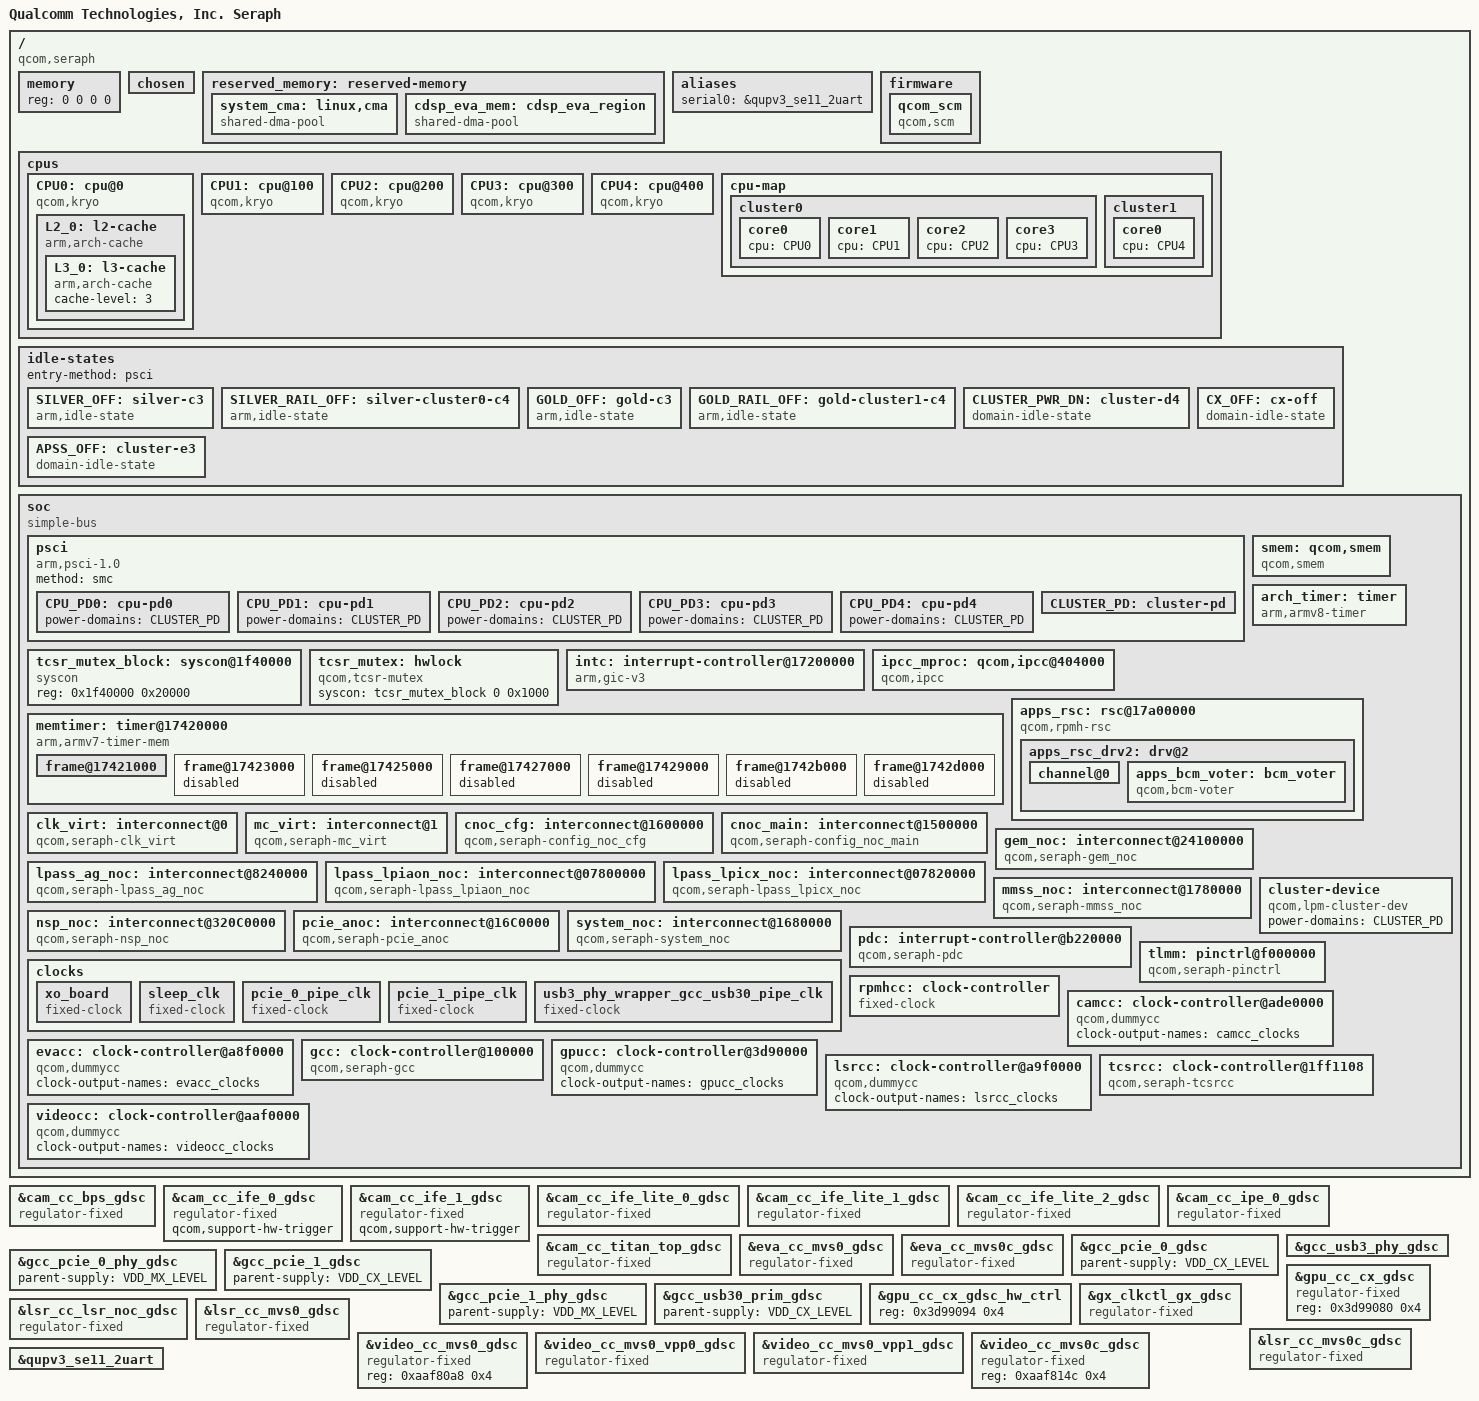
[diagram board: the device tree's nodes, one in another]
#include <dt-bindings/interrupt-controller/arm-gic.h>
#include <dt-bindings/soc/qcom,rpmh-rsc.h>
#include <dt-bindings/clock/qcom,rpmh.h>
#include <dt-bindings/clock/qcom,camcc-seraph.h>
#include <dt-bindings/clock/qcom,evacc-seraph.h>
#include <dt-bindings/clock/qcom,gcc-seraph.h>
#include <dt-bindings/clock/qcom,gpucc-seraph.h>
#include <dt-bindings/clock/qcom,lsrcc-seraph.h>
#include <dt-bindings/clock/qcom,tcsrcc-seraph.h>
#include <dt-bindings/clock/qcom,videocc-seraph.h>
#include <dt-bindings/interconnect/qcom,seraph.h>
#include <dt-bindings/mailbox/qcom-ipcc.h>
#include <dt-bindings/regulator/qcom,rpmh-regulator-levels.h>

/ {
	model = "Qualcomm Technologies, Inc. Seraph";
	compatible = "qcom,seraph";
	qcom,msm-id = <672 0x10000>;
	interrupt-parent = <&intc>;

	#address-cells = <2>;
	#size-cells = <2>;
	memory { device_type = "memory"; reg = <0 0 0 0>; };

	chosen: chosen {
		bootargs = "kpti=0 log_buf_len=256K swiotlb=0 loop.max_part=7 loglevel=8";
	};

	reserved_memory: reserved-memory {};

	aliases {
		serial0 = &qupv3_se11_2uart;
	 };

	firmware: firmware {};

	cpus {
		#address-cells = <2>;
		#size-cells = <0>;

		CPU0: cpu@0 {
			device_type = "cpu";
			compatible = "qcom,kryo";
			reg = <0x0 0x0>;
			enable-method = "psci";
			cpu-idle-states = <&SILVER_OFF &SILVER_RAIL_OFF>;
			power-domains = <&CPU_PD0>;
			power-domain-names = "psci";
			next-level-cache = <&L2_0>;
			capacity-dmips-mhz = <1024>;
			dynamic-power-coefficient = <100>;
			L2_0: l2-cache {
				compatible = "arm,arch-cache";
				cache-level = <2>;
				next-level-cache = <&L3_0>;

				L3_0: l3-cache {
					compatible = "arm,arch-cache";
					cache-level = <3>;
				};
			};
		};

		CPU1: cpu@100 {
			device_type = "cpu";
			compatible = "qcom,kryo";
			reg = <0x0 0x100>;
			enable-method = "psci";
			cpu-idle-states = <&SILVER_OFF &SILVER_RAIL_OFF>;
			power-domains = <&CPU_PD1>;
			power-domain-names = "psci";
			next-level-cache = <&L2_0>;
			capacity-dmips-mhz = <1024>;
			dynamic-power-coefficient = <100>;
		};

		CPU2: cpu@200 {
			device_type = "cpu";
			compatible = "qcom,kryo";
			reg = <0x0 0x200>;
			enable-method = "psci";
			cpu-idle-states = <&SILVER_OFF &SILVER_RAIL_OFF>;
			power-domains = <&CPU_PD2>;
			power-domain-names = "psci";
			next-level-cache = <&L2_0>;
			capacity-dmips-mhz = <1024>;
			dynamic-power-coefficient = <100>;
		};

		CPU3: cpu@300 {
			device_type = "cpu";
			compatible = "qcom,kryo";
			reg = <0x0 0x300>;
			enable-method = "psci";
			cpu-idle-states = <&SILVER_OFF &SILVER_RAIL_OFF>;
			power-domains = <&CPU_PD3>;
			power-domain-names = "psci";
			next-level-cache = <&L2_0>;
			capacity-dmips-mhz = <1024>;
			dynamic-power-coefficient = <100>;
		};

		CPU4: cpu@400 {
			device_type = "cpu";
			compatible = "qcom,kryo";
			reg = <0x0 0x400>;
			enable-method = "psci";
			cpu-idle-states = <&GOLD_OFF &GOLD_RAIL_OFF>;
			power-domains = <&CPU_PD4>;
			power-domain-names = "psci";
			next-level-cache = <&L2_0>;
			capacity-dmips-mhz = <1956>;
			dynamic-power-coefficient = <389>;
		};

		cpu-map {
			cluster0 {
				core0 {
					cpu = <&CPU0>;
				};

				core1 {
					cpu = <&CPU1>;
				};

				core2 {
					cpu = <&CPU2>;
				};

				core3 {
					cpu = <&CPU3>;
				};
			};

			cluster1 {
				core0 {
					cpu = <&CPU4>;
				};
			};
		};
	};

	idle-states {
		entry-method = "psci";

		SILVER_OFF: silver-c3 {  /* C3 */
			compatible = "arm,idle-state";
			idle-state-name = "pc";
			entry-latency-us = <250>;
			exit-latency-us = <900>;
			min-residency-us = <3200>;
			arm,psci-suspend-param = <0x40000003>;
			local-timer-stop;
		};

		SILVER_RAIL_OFF: silver-cluster0-c4 { /* C4 */
			compatible = "arm,idle-state";
			idle-state-name = "rail-pc";
			entry-latency-us = <550>;
			exit-latency-us = <750>;
			min-residency-us = <6700>;
			arm,psci-suspend-param = <0x40000004>;
			local-timer-stop;
		};

		GOLD_OFF: gold-c3 {  /* C3 */
			compatible = "arm,idle-state";
			idle-state-name = "pc";
			entry-latency-us = <400>;
			exit-latency-us = <1100>;
			min-residency-us = <4011>;
			arm,psci-suspend-param = <0x40000003>;
			local-timer-stop;
		};

		GOLD_RAIL_OFF: gold-cluster1-c4 { /* C4 */
			compatible = "arm,idle-state";
			idle-state-name = "rail-pc";
			entry-latency-us = <550>;
			exit-latency-us = <1050>;
			min-residency-us = <7951>;
			arm,psci-suspend-param = <0x40000004>;
			local-timer-stop;
		};

		CLUSTER_PWR_DN: cluster-d4 { /* D4 */
			compatible = "domain-idle-state";
			idle-state-name = "l3-off";
			entry-latency-us = <750>;
			exit-latency-us = <2350>;
			min-residency-us = <9144>;
			arm,psci-suspend-param = <0x41000044>;
		};

		CX_OFF: cx-off { /* Cx Off */
			compatible = "domain-idle-state";
			idle-state-name = "cx-ret";
			entry-latency-us = <1561>;
			exit-latency-us = <2801>;
			min-residency-us = <8550>;
			arm,psci-suspend-param = <0x41002344>;
		};

		APSS_OFF: cluster-e3 { /* E3 */
			compatible = "domain-idle-state";
			idle-state-name = "llcc-off";
			entry-latency-us = <2800>;
			exit-latency-us = <4400>;
			min-residency-us = <10150>;
			arm,psci-suspend-param = <0x4100c344>;
		};
	};

	soc: soc { };

};

&soc {
	#address-cells = <1>;
	#size-cells = <1>;

	ranges = <0 0 0 0xffffffff>;
	compatible = "simple-bus";

	psci {
		compatible = "arm,psci-1.0";
		method = "smc";

		CPU_PD0: cpu-pd0 {
			#power-domain-cells = <0>;
			power-domains = <&CLUSTER_PD>;
		};

		CPU_PD1: cpu-pd1 {
			#power-domain-cells = <0>;
			power-domains = <&CLUSTER_PD>;
		};

		CPU_PD2: cpu-pd2 {
			#power-domain-cells = <0>;
			power-domains = <&CLUSTER_PD>;
		};

		CPU_PD3: cpu-pd3 {
			#power-domain-cells = <0>;
			power-domains = <&CLUSTER_PD>;
		};

		CPU_PD4: cpu-pd4 {
			#power-domain-cells = <0>;
			power-domains = <&CLUSTER_PD>;
		};

		CLUSTER_PD: cluster-pd {
			#power-domain-cells = <0>;
			domain-idle-states = <&CLUSTER_PWR_DN &CX_OFF &APSS_OFF>;
		};
	};

	tcsr_mutex_block: syscon@1f40000 {
		compatible = "syscon";
		reg = <0x1f40000 0x20000>;
	};

	tcsr_mutex: hwlock {
		compatible = "qcom,tcsr-mutex";
		syscon = <&tcsr_mutex_block 0 0x1000>;
		#hwlock-cells = <1>;
	};

	smem: qcom,smem {
		compatible = "qcom,smem";
		memory-region = <&smem_mem>;
		hwlocks = <&tcsr_mutex 3>;
	};

	intc: interrupt-controller@17200000 {
		compatible = "arm,gic-v3";
		#interrupt-cells = <3>;
		interrupt-controller;
		#redistributor-regions = <1>;
		redistributor-stride = <0x0 0x20000>;
		reg = <0x17200000 0x10000>,       /* GICD */
		     <0x17260000 0xA0000>;       /* GICR * 5 */
		interrupts = <GIC_PPI 9 IRQ_TYPE_LEVEL_HIGH>;
	};

	arch_timer: timer {
		compatible = "arm,armv8-timer";
		interrupts = <GIC_PPI 13 (GIC_CPU_MASK_SIMPLE(8) | IRQ_TYPE_LEVEL_LOW)>,
			     <GIC_PPI 14 (GIC_CPU_MASK_SIMPLE(8) | IRQ_TYPE_LEVEL_LOW)>,
			     <GIC_PPI 11 (GIC_CPU_MASK_SIMPLE(8) | IRQ_TYPE_LEVEL_LOW)>,
			     <GIC_PPI 12 (GIC_CPU_MASK_SIMPLE(8) | IRQ_TYPE_LEVEL_LOW)>;
		clock-frequency = <19200000>;
	};

	ipcc_mproc: qcom,ipcc@404000 {
		compatible = "qcom,ipcc";
		reg = <0x404000 0x1000>;
		interrupts = <GIC_SPI 229 IRQ_TYPE_LEVEL_HIGH>;
		interrupt-controller;
		#interrupt-cells = <3>;
		#mbox-cells = <2>;
	};

	memtimer: timer@17420000 {
		#address-cells = <1>;
		#size-cells = <1>;
		ranges;
		compatible = "arm,armv7-timer-mem";
		reg = <0x17420000 0x1000>;
		clock-frequency = <19200000>;

		frame@17421000 {
			frame-number = <0>;
			interrupts = <GIC_SPI 8 IRQ_TYPE_LEVEL_HIGH>,
				     <GIC_SPI 6 IRQ_TYPE_LEVEL_HIGH>;
			reg = <0x17421000 0x1000>,
			      <0x17422000 0x1000>;
		};

		frame@17423000 {
			frame-number = <1>;
			interrupts = <GIC_SPI 9 IRQ_TYPE_LEVEL_HIGH>;
			reg = <0x17423000 0x1000>;
			status = "disabled";
		};

		frame@17425000 {
			frame-number = <2>;
			interrupts = <GIC_SPI 10 IRQ_TYPE_LEVEL_HIGH>;
			reg = <0x17425000 0x1000>;
			status = "disabled";
		};

		frame@17427000 {
			frame-number = <3>;
			interrupts = <GIC_SPI 11 IRQ_TYPE_LEVEL_HIGH>;
			reg = <0x17427000 0x1000>;
			status = "disabled";
		};

		frame@17429000 {
			frame-number = <4>;
			interrupts = <GIC_SPI 12 IRQ_TYPE_LEVEL_HIGH>;
			reg = <0x17429000 0x1000>;
			status = "disabled";
		};

		frame@1742b000 {
			frame-number = <5>;
			interrupts = <GIC_SPI 13 IRQ_TYPE_LEVEL_HIGH>;
			reg = <0x1742b000 0x1000>;
			status = "disabled";
		};

		frame@1742d000 {
			frame-number = <6>;
			interrupts = <GIC_SPI 14 IRQ_TYPE_LEVEL_HIGH>;
			reg = <0x1742d000 0x1000>;
			status = "disabled";
		};
	};

	apps_rsc: rsc@17a00000 {
		label = "apps_rsc";
		compatible = "qcom,rpmh-rsc";
		reg = <0x17a00000 0x10000>,
		      <0x17a10000 0x10000>,
		      <0x17a20000 0x10000>;
		reg-names = "drv-0", "drv-1", "drv-2";
		qcom,drv-count = <3>;
		interrupts = <GIC_SPI 3 IRQ_TYPE_LEVEL_HIGH>,
			     <GIC_SPI 4 IRQ_TYPE_LEVEL_HIGH>,
			     <GIC_SPI 5 IRQ_TYPE_LEVEL_HIGH>;
		power-domains = <&CLUSTER_PD>;

		apps_rsc_drv2: drv@2 {
			qcom,drv-id = <2>;
			qcom,tcs-offset = <0xd00>;
			qcom,tcs-distance = <0x2a0>;
			channel@0 {
				qcom,tcs-config = <ACTIVE_TCS    3>,
						  <SLEEP_TCS     2>,
						  <WAKE_TCS      2>,
						  <CONTROL_TCS   0>,
						  <FAST_PATH_TCS 1>;
			};

			apps_bcm_voter: bcm_voter {
				compatible = "qcom,bcm-voter";
			};
		};
	};

	clk_virt: interconnect@0 {
		compatible = "qcom,seraph-clk_virt";
		#interconnect-cells = <1>;
		qcom,bcm-voter-names = "hlos";
		qcom,bcm-voters = <&apps_bcm_voter>;
	};

	mc_virt: interconnect@1 {
		compatible = "qcom,seraph-mc_virt";
		#interconnect-cells = <1>;
		qcom,bcm-voter-names = "hlos";
		qcom,bcm-voters = <&apps_bcm_voter>;
	};

	cnoc_cfg: interconnect@1600000 {
		compatible = "qcom,seraph-config_noc_cfg";
		reg = <0x01600000 0x7200>;
		#interconnect-cells = <1>;
		qcom,bcm-voter-names = "hlos";
		qcom,bcm-voters = <&apps_bcm_voter>;
		qcom,skip-qos;
	};

	cnoc_main: interconnect@1500000 {
		compatible = "qcom,seraph-config_noc_main";
		reg = <0x01500000 0x1a200>;
		#interconnect-cells = <1>;
		qcom,bcm-voter-names = "hlos";
		qcom,bcm-voters = <&apps_bcm_voter>;
		qcom,skip-qos;
	};

	gem_noc: interconnect@24100000 {
		compatible = "qcom,seraph-gem_noc";
		reg = <0x24100000 0x163080>;
		#interconnect-cells = <1>;
		qcom,bcm-voter-names = "hlos";
		qcom,bcm-voters = <&apps_bcm_voter>;
		qcom,skip-qos;
	};

	lpass_ag_noc: interconnect@8240000 {
		compatible = "qcom,seraph-lpass_ag_noc";
		reg = <0x08240000 0xe080>;
		#interconnect-cells = <1>;
		qcom,bcm-voter-names = "hlos";
		qcom,bcm-voters = <&apps_bcm_voter>;
		qcom,skip-qos;
	};

	lpass_lpiaon_noc: interconnect@07800000 {
		compatible = "qcom,seraph-lpass_lpiaon_noc";
		reg = <0x07800000 0x19080>;
		#interconnect-cells = <1>;
		qcom,bcm-voter-names = "hlos";
		qcom,bcm-voters = <&apps_bcm_voter>;
		qcom,skip-qos;
	};

	lpass_lpicx_noc: interconnect@07820000 {
		compatible = "qcom,seraph-lpass_lpicx_noc";
		reg = <0x07820000 0x44080>;
		#interconnect-cells = <1>;
		qcom,bcm-voter-names = "hlos";
		qcom,bcm-voters = <&apps_bcm_voter>;
		qcom,skip-qos;
	};

	mmss_noc: interconnect@1780000 {
		compatible = "qcom,seraph-mmss_noc";
		reg = <0x01780000 0x6b800>;
		#interconnect-cells = <1>;
		qcom,bcm-voter-names = "hlos";
		qcom,bcm-voters = <&apps_bcm_voter>;
		qcom,skip-qos;
	};

	nsp_noc: interconnect@320C0000 {
		compatible = "qcom,seraph-nsp_noc";
		reg = <0x320C0000 0x1f400>;
		#interconnect-cells = <1>;
		qcom,bcm-voter-names = "hlos";
		qcom,bcm-voters = <&apps_bcm_voter>;
		qcom,skip-qos;
	};

	pcie_anoc: interconnect@16C0000 {
		compatible = "qcom,seraph-pcie_anoc";
		reg = <0x016C0000 0xe400>;
		#interconnect-cells = <1>;
		qcom,bcm-voter-names = "hlos";
		qcom,bcm-voters = <&apps_bcm_voter>;
		qcom,skip-qos;
	};

	system_noc: interconnect@1680000 {
		compatible = "qcom,seraph-system_noc";
		reg = <0x01680000 0x2d800>;
		#interconnect-cells = <1>;
		qcom,bcm-voter-names = "hlos";
		qcom,bcm-voters = <&apps_bcm_voter>;
		qcom,skip-qos;
	};

	pdc: interrupt-controller@b220000 {
		compatible = "qcom,seraph-pdc", "qcom,pdc";
		reg = <0xb220000 0x10000>, <0x174000f0 0x64>;
		qcom,pdc-ranges = <0 221 1>, <1 227 2>, <3 238 4>,
				  <8 263 2>, <10 293 3>, <14 297 2>,
				  <16 348 2>, <18 351 3>, <22 355 2>,
				  <24 641 1>, <25 358 1>, <26 376 2>,
				  <28 443 1>, <30 242 1>, <31 296 1>,
				  <32 354 1>, <33 357 1>, <34 444 3>,
				  <37 472 1>, <40 447 1>, <41 461 1>,
				  <42 473 1>, <43 462 1>, <44 584 1>,
				  <45 586 1>, <47 607 2>, <49 642 1>,
				  <50 656 1>, <51 527 1>, <61 505 1>,
				  <62 605 1>, <63 372 2>, <65 378 1>,
				  <66 431 1>, <70 528 46>, <116 609 31>,
				  <147 63 1>, <148 716 12>, <160 251 5>,
				  <165 379 1>;
		#interrupt-cells = <2>;
		interrupt-parent = <&intc>;
		interrupt-controller;
	};

	cluster-device {
		compatible = "qcom,lpm-cluster-dev";
		power-domains = <&CLUSTER_PD>;
	};

	tlmm: pinctrl@f000000 {
		compatible = "qcom,seraph-pinctrl";
		reg = <0x0F000000 0x1000000>;
		interrupts = <GIC_SPI 208 IRQ_TYPE_LEVEL_HIGH>;
		gpio-controller;
		#gpio-cells = <2>;
		interrupt-controller;
		#interrupt-cells = <2>;
		wakeup-parent = <&pdc>;
	};

	clocks {
		xo_board: xo_board {
			compatible = "fixed-clock";
			clock-frequency = <38400000>;
			clock-output-names = "xo_board";
			#clock-cells = <0>;
		};

		sleep_clk: sleep_clk {
			compatible = "fixed-clock";
			clock-frequency = <32000>;
			clock-output-names = "sleep_clk";
			#clock-cells = <0>;
		};

		pcie_0_pipe_clk: pcie_0_pipe_clk {
			compatible = "fixed-clock";
			clock-frequency = <1000>;
			clock-output-names = "pcie_0_pipe_clk";
			#clock-cells = <0>;
		};

		pcie_1_pipe_clk: pcie_1_pipe_clk {
			compatible = "fixed-clock";
			clock-frequency = <1000>;
			clock-output-names = "pcie_1_pipe_clk";
			#clock-cells = <0>;
		};

		usb3_phy_wrapper_gcc_usb30_pipe_clk: usb3_phy_wrapper_gcc_usb30_pipe_clk {
			compatible = "fixed-clock";
			clock-frequency = <1000>;
			clock-output-names = "usb3_phy_wrapper_gcc_usb30_pipe_clk";
			#clock-cells = <0>;
		};
	};

	rpmhcc: clock-controller {
		compatible = "fixed-clock";
		clock-output-names = "rpmh_clocks";
		clock-frequency = <19200000>;
		#clock-cells = <1>;
	};

	camcc: clock-controller@ade0000 {
		compatible = "qcom,dummycc";
		clock-output-names = "camcc_clocks";
		#clock-cells = <1>;
		#reset-cells = <1>;
	};

	evacc: clock-controller@a8f0000 {
		compatible = "qcom,dummycc";
		clock-output-names = "evacc_clocks";
		#clock-cells = <1>;
		#reset-cells = <1>;
	};

	gcc: clock-controller@100000 {
		compatible = "qcom,seraph-gcc", "syscon";
		reg = <0x100000 0x1f4200>;
		reg-name = "cc_base";
		vdd_cx-supply = <&VDD_CX_LEVEL>;
		vdd_mx-supply = <&VDD_MX_LEVEL>;
		clocks = <&rpmhcc RPMH_CXO_CLK>,
			 <&pcie_0_pipe_clk>,
			 <&pcie_1_pipe_clk>,
			 <&sleep_clk>,
			 <&usb3_phy_wrapper_gcc_usb30_pipe_clk>;
		clock-names = "bi_tcxo",
			      "pcie_0_pipe_clk",
			      "pcie_1_pipe_clk",
			      "sleep_clk",
			      "usb3_phy_wrapper_gcc_usb30_pipe_clk";
		#clock-cells = <1>;
		#reset-cells = <1>;
	};

	gpucc: clock-controller@3d90000 {
		compatible = "qcom,dummycc";
		clock-output-names = "gpucc_clocks";
		#clock-cells = <1>;
		#reset-cells = <1>;
	};

	lsrcc: clock-controller@a9f0000 {
		compatible = "qcom,dummycc";
		clock-output-names = "lsrcc_clocks";
		#clock-cells = <1>;
		#reset-cells = <1>;
	};

	tcsrcc: clock-controller@1ff1108 {
		compatible = "qcom,seraph-tcsrcc", "syscon";
		reg = <0x1ff1108 0x18>;
		reg-name = "cc_base";
		#clock-cells = <1>;
		#reset-cells = <1>;
	};

	videocc: clock-controller@aaf0000 {
		compatible = "qcom,dummycc";
		clock-output-names = "videocc_clocks";
		#clock-cells = <1>;
		#reset-cells = <1>;
	};
};

#include "pineapple-gdsc.dtsi"

&cam_cc_bps_gdsc {
	compatible = "regulator-fixed";
	status = "ok";
};

&cam_cc_ife_0_gdsc {
	compatible = "regulator-fixed";
	qcom,support-hw-trigger;
	status = "ok";
};

&cam_cc_ife_1_gdsc {
	compatible = "regulator-fixed";
	qcom,support-hw-trigger;
	status = "ok";
};

&cam_cc_ife_lite_0_gdsc {
	compatible = "regulator-fixed";
	status = "ok";
};

&cam_cc_ife_lite_1_gdsc {
	compatible = "regulator-fixed";
	status = "ok";
};

&cam_cc_ife_lite_2_gdsc {
	compatible = "regulator-fixed";
	status = "ok";
};

&cam_cc_ipe_0_gdsc {
	compatible = "regulator-fixed";
	status = "ok";
};

&cam_cc_titan_top_gdsc {
	compatible = "regulator-fixed";
	reg = <0xadf4028 0x4>;
	qcom,support-hw-trigger;
	status = "ok";
};

&eva_cc_mvs0_gdsc {
	compatible = "regulator-fixed";
	status = "ok";
};

&eva_cc_mvs0c_gdsc {
	compatible = "regulator-fixed";
	status = "ok";
};

&gcc_pcie_0_gdsc {
	parent-supply = <&VDD_CX_LEVEL>;
	status = "ok";
};

&gcc_pcie_0_phy_gdsc {
	parent-supply = <&VDD_MX_LEVEL>;
	status = "ok";
};

&gcc_pcie_1_gdsc {
	parent-supply = <&VDD_CX_LEVEL>;
	status = "ok";
};

&gcc_pcie_1_phy_gdsc {
	parent-supply = <&VDD_MX_LEVEL>;
	status = "ok";
};

&gcc_usb30_prim_gdsc {
	parent-supply = <&VDD_CX_LEVEL>;
	status = "ok";
};

&gcc_usb3_phy_gdsc {
	parent-supply = <&VDD_MX_LEVEL>;
	reg = <0x15000c 0x4>;
	status = "ok";
};

&gpu_cc_cx_gdsc_hw_ctrl {
	reg = <0x3d99094 0x4>;
};

&gpu_cc_cx_gdsc {
	compatible = "regulator-fixed";
	reg = <0x3d99080 0x4>;
	status = "ok";
};

&gx_clkctl_gx_gdsc {
	compatible = "regulator-fixed";
	status = "ok";
};

&lsr_cc_lsr_noc_gdsc {
	compatible = "regulator-fixed";
	status = "ok";
};

&lsr_cc_mvs0_gdsc {
	compatible = "regulator-fixed";
	status = "ok";
};

&lsr_cc_mvs0c_gdsc {
	compatible = "regulator-fixed";
	status = "ok";
};

&video_cc_mvs0_gdsc {
	compatible = "regulator-fixed";
	reg = <0xaaf80a8 0x4>;
	status = "ok";
};

&video_cc_mvs0_vpp0_gdsc {
	compatible = "regulator-fixed";
	status = "ok";
};

&video_cc_mvs0_vpp1_gdsc {
	compatible = "regulator-fixed";
	status = "ok";
};

&video_cc_mvs0c_gdsc {
	compatible = "regulator-fixed";
	reg = <0xaaf814c 0x4>;
	status = "ok";
};

#include "seraph-pinctrl.dtsi"
#include "seraph-qupv3.dtsi"
#include "ipcc-test-seraph.dtsi"

&qupv3_se11_2uart {
	status = "ok";
};

#include "seraph-stub-regulators.dtsi"

&reserved_memory {
	#address-cells = <2>;
	#size-cells = <2>;
	ranges;

	/* global autoconfigured region for contiguous allocations */
	system_cma: linux,cma {
		compatible = "shared-dma-pool";
		alloc-ranges = <0x0 0x00000000 0x0 0xffffffff>;
		reusable;
		alignment = <0x0 0x400000>;
		size = <0x0 0x2000000>;
		linux,cma-default;
	};

	/* cdsp eva shared memory */
	cdsp_eva_mem: cdsp_eva_region {
		compatible = "shared-dma-pool";
		alloc-ranges = <0x0 0x00000000 0x0 0xffffffff>;
		reusable;
		alignment = <0x0 0x400000>;
		size = <0x0 0x400000>;
	};
};

&firmware {
	qcom_scm {
		compatible = "qcom,scm";
	};
};


#include "seraph-reserved-memory.dtsi"
#include "seraph-dma-heaps.dtsi"
#include "msm-arm-smmu-seraph.dtsi"
#include "seraph-usb.dtsi"
